VERSION ""

NS_ :

BS_:

BU_: ESP

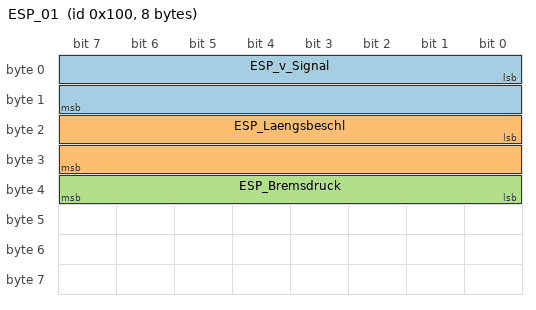
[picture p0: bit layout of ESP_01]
BO_ 256 ESP_01: 8 ESP
 SG_ ESP_v_Signal : 0|16@1+ (0.01,0) [0|655.35] "km/h" ESP
 SG_ ESP_Laengsbeschl : 16|16@1- (0.01,-327.68) [-327.68|327.67] "m/s^2" ESP
 SG_ ESP_Bremsdruck : 32|8@1+ (0.4,0) [0|100] "%" ESP
